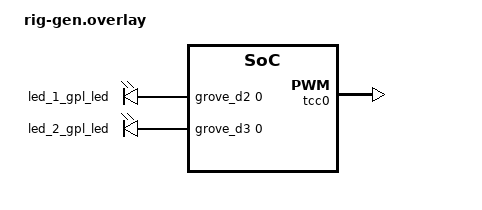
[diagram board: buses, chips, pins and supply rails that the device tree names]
/* generated by rigc — do not edit; the rig file is the source of truth
 * rig: lotus_pwm_led  board: seeeduino_lotus/samd21g18a/rig
 */

/ {
	pwm_leds: pwm_leds {
		compatible = "pwm-leds";
		led_1_gpl_led: led_1_gpl_led {
			label = "led_1_gpl_led";
			pwms = <&grove_d2 0 20000000>;	/* SIG0 */
		};
		led_2_gpl_led: led_2_gpl_led {
			label = "led_2_gpl_led";
			pwms = <&grove_d3 0 20000000>;	/* SIG0 */
		};
	};
};

/* PWM/ADC: enable the resolved controllers; the pin-mux (pinctrl)
 * for each muxed pin is board-provided and must be applied —
 * stubbed here, see the config sheet. */
&tcc0 { status = "okay"; };
